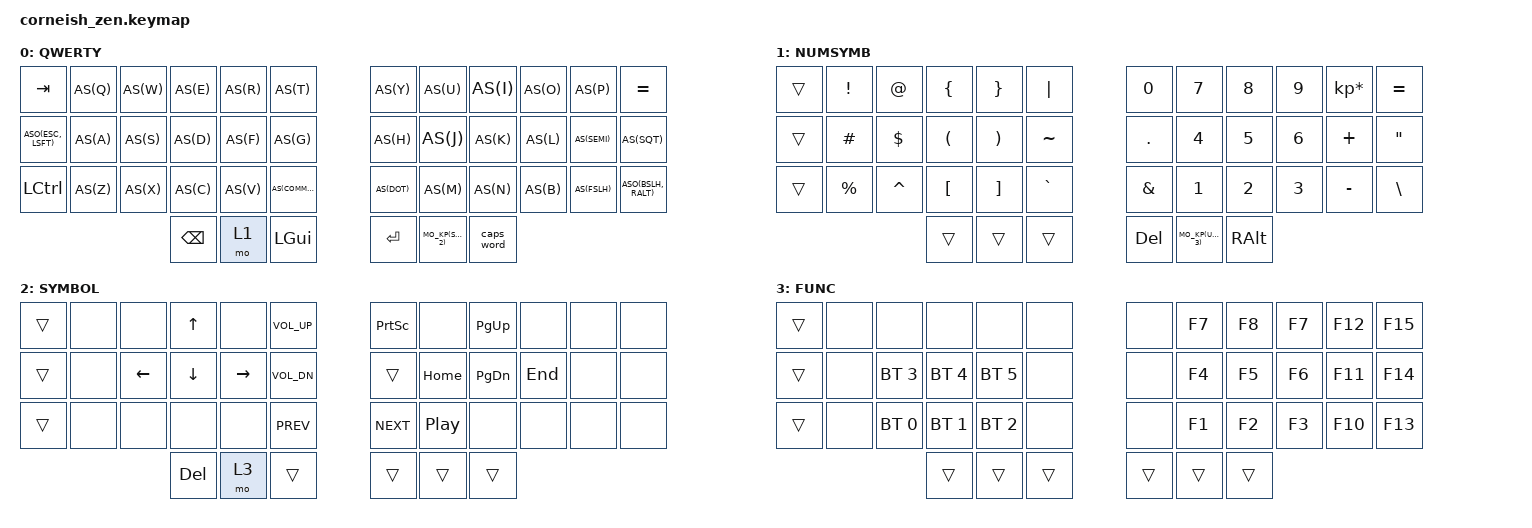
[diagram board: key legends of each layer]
#include <behaviors.dtsi>
#include <dt-bindings/zmk/keys.h>
#include <dt-bindings/zmk/bt.h>

#define AS(keycode) &as LS(keycode) keycode // Autoshift Macro
#define ASO(keycode1, keycode2) &as keycode2 keycode1
#define MO_KP(keycode, layer) &mo_kp layer keycode

/ {
  chosen {
    zmk,matrix_transform = &default_transform;
    //zmk,matrix_transform = &five_column_transform;
  };
};

/ {
        behaviors {
                as: auto_shift {
                        compatible = "zmk,behavior-hold-tap";
                        label = "AUTO_SHIFT";
                        #binding-cells = <2>;
                        tapping_term_ms = <145>;
                        quick_tap_ms = <0>;
                        flavor = "tap-preferred";
                        bindings = <&kp>, <&kp>;
                };

                mo_kp: behavior_mo_kp {
                        compatible = "zmk,behavior-hold-tap";
                        label = "MO_KP";
                        #binding-cells = <2>;
                        flavor = "balanced";
                        tapping_term_ms = <150>;
                        bindings = <&mo>, <&kp>;
                };
        };

        keymap {
                compatible = "zmk,keymap";

                default_layer {
                        label = "QWERTY";
// -----------------------------------------------------------------------------------------
// | TAB  |  Q  |  W  |  E  |  R  |  T  |   |  Y  |  U   |  I  |  O  |  P  | =   |
// | ESC  |  A  |  S  |  D  |  F  |  G  |   |  H  |  J   |  K  |  L  |  ;  |  '  |
// | CTRL |  Z  |  X  |  C  |  V  |  ,  |   |  .  |  M   |  N  |  B  |  /  |  \  |
//                    | BKS | LWR | SPC |   | ENT | RSE  | ALT |
                        bindings = <
   &kp TAB          AS(Q) AS(W) AS(E) AS(R) AS(T)     AS(Y)   AS(U) AS(I) AS(O) AS(P)    &kp EQUAL
   ASO(ESC, LSFT)   AS(A) AS(S) AS(D) AS(F) AS(G)     AS(H)   AS(J) AS(K) AS(L) AS(SEMI) AS(SQT)
   &kp LCTRL        AS(Z) AS(X) AS(C) AS(V) AS(COMMA) AS(DOT) AS(M) AS(N) AS(B) AS(FSLH) ASO(BSLH, RALT)
                                      &kp BKSP &mo 1 &kp LGUI  &kp RET MO_KP(SPACE, 2) &caps_word
                        >;
                };

                lower_layer {
                        label = "NUMSYMB";
// -----------------------------------------------------------------------------------------
// | TAB  |  !  |  @  |  {  |  }  |  |  |   |  0  |  7  |  8  |  9  |  *  |  =  |
// | ESC  |  #  |  $  |  (  |  )  |  ~  |   |  .  |  4  |  5  |  6  |  +  |  "  |
// | CTRL |  %  |  ^  |  [  |  ]  |  `  |   |  &  |  1  |  2  |  3  |  -  |  \  |
//                    | GUI |     | SPC |   | DEL |  _  | ALT |
                        bindings = <
   &trans     &kp EXCL     &kp AT       &kp LBRC     &kp RBRC     &kp PIPE       &kp N0   &kp N7   &kp N8   &kp N9    &kp KP_MULTIPLY &kp EQUAL
   &trans     &kp HASH     &kp DLLR     &kp LPAR     &kp RPAR     &kp TILDE      &kp DOT  &kp N4   &kp N5   &kp N6    &kp PLUS        &kp DQT
   &trans     &kp PRCNT    &kp CARET    &kp LBKT     &kp RBKT     &kp GRAVE      &kp AMPS &kp N1   &kp N2   &kp N3    &kp MINUS       &kp BSLH
                                        &trans       &trans       &trans         &kp DEL   MO_KP(UNDER, 3) &kp RALT
                        >;
                };

                raise_layer {
                        label = "SYMBOL";
// -----------------------------------------------------------------------------------------
// | TAB  |     |      |  UP  |       | VOL+ |   | PRSCR |      | PGUP |     |     |      |
// | ESC  |     | LEFT | DOWN | RIGHT | VOL- |   |       | HOME | PGDN | END |     |      |
// | CTRL |     |      |      |       | PREV |   | NEXT  | PLPS |      |     |     |      |
//                     | DEL  |       | SPC  |   | ENT   |      | ALT  |
                        bindings = <
   &trans    &none   &none    &kp UP   &none     &kp C_VOL_UP &kp PSCRN   &none    &kp PG_UP   &none    &none &none
   &trans    &none   &kp LEFT &kp DOWN &kp RIGHT &kp C_VOL_DN &trans      &kp HOME &kp PG_DN   &kp END  &none &none
   &trans    &none   &none    &none    &none     &kp C_PREV   &kp C_NEXT  &kp C_PP &none       &none    &none &none
                              &kp DEL  &mo 3     &trans       &trans      &trans   &trans
                        >;
                };

                function_layer {
                        label = "FUNC";
// -----------------------------------------------------------------------------------------
// | TAB  |     |      |      |      |      |   |    | F7 | F8 | F9 | F12 | F15 |
// | ESC  |     | BT 3 | BT 4 | BT 5 |      |   |    | F4 | F5 | F6 | F11 | F14 |
// | CTRL |     | BT 0 | BT 1 | BT 2 |      |   |    | F1 | F2 | F3 | F10 | F13 |
//                     |      |      |      |   |    |    |      |
                        bindings = <
   &trans    &none &none        &none        &none        &none           &none &kp F7 &kp F8 &kp F7 &kp F12 &kp F15
   &trans    &none &bt BT_SEL 3 &bt BT_SEL 4 &bt BT_SEL 5 &none           &none &kp F4 &kp F5 &kp F6 &kp F11 &kp F14
   &trans    &none &bt BT_SEL 0 &bt BT_SEL 1 &bt BT_SEL 2 &none           &none &kp F1 &kp F2 &kp F3 &kp F10 &kp F13
                              &trans &trans &trans   &trans &trans &trans
                        >;
                };
        };
};
